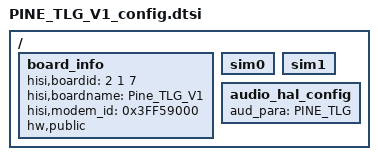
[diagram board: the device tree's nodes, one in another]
/*
 * Hisilicon Ltd.
 *
 * A15x4 A7x4
 *
 * It is only a demo for hisilicon hi3630 board. You show change the
 * address of each node according to datasheet.
 */


/include/ "hisi_sim_hotplug.dtsi"

/include/ "PINE_TLGULG_V1_config.dtsi"
/include/ "hisi_3630_pin_PINE_TLG_V1.dtsi"
/include/ "hisi_3630_modem_PINE_TLG_V1.dtsi"
/ {
	board_info: board_info {
		hisi,boardid = <2 1 7>;
		hisi,boardname = "Pine_TLG_V1";
		hisi,modem_id = <0x3FF59000>;
		hw,public;
	};

	sim0 {
		status = "ok";
	};
	sim1 {
		status = "ok";
	};
	audio_hal_config {
		aud_para = "PINE_TLG";
	};
};
